# SAMA7G54D4GN8 register map
Vendor: Microchip Technology; Series: SAMA7G5; File version: 0
Registers are 32-bit, read-write, reset 0x0 unless marked. A register's access mark holds for its fields unless they carry their own. Offsets are from the block's base; [hi:lo] are bit positions; {n}, {i} and the like mark numbered series; 'fields as' and 'values as' point back to an identical list.

## EIC — External Interrupt Controller
Base 0xE1628000
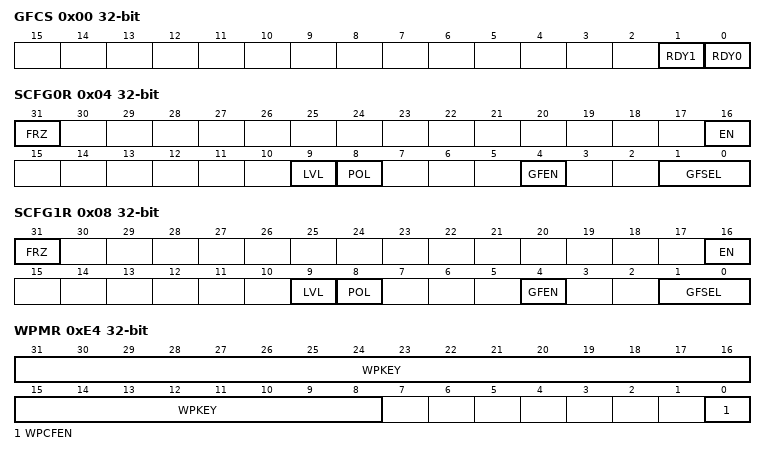
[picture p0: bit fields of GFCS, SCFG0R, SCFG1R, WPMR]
0x00 GFCS ro — Glitch Filter Configuration Status Register
  [1] RDY1 — Filter 1 Configuration Ready
    0=The interrupt line x glitch filter is not yet ready for use due to a previous write to IP_Acronym_SCFGxR, or the glitch filter is not implemented for this interrupt line. The glitch filter must not be reprogrammed in EIC_SCFGxR.; 1=The interrupt line x glitch filter configuration is done and the glitch filter is active. The glitch filter can be programmed in EIC_SCFGxR.
  [0] RDY0 — Filter 0 Configuration Ready
    values as RDY1
0x04 SCFG0R — Source Configuration Register 0
  [31] FRZ — Interrupt Line Freeze
    0=No effect; 1=EIC_SCFGxR is frozen until hardware reset
  [16] EN — Source Enable
    0=The EIC source x is disabled. Any source edge or level detection is discarded.; 1=The EIC source x is enabled
  [9] LVL — Level Detection
    0=The EIC source x interrupt status is set on a valid source edge; 1=The EIC source x interrupt status is set on a valid source level
  [8] POL — Polarity
    0=The EIC source x is active low if LVL is set, or active on falling edge if LVL is cleared; 1=The EIC source x is active high if LVL is set, or active on rising edge if LVL is cleared
  [4] GFEN — Glitch Filter Enable
    0=The glitch filter is disabled or not implemented for EIC source x. Any source x change is forwarded as is to the source detection logic.; 1=The glitch filter is enabled for EIC source x. The EIC source x glitches are filtered according to Section 7.1 'Interrupt Line Characteristics'.
  [1:0] GFSEL — Glitch Filter Selector
0x08 SCFG1R — Source Configuration Register 1
  fields as SCFG0R
0xE4 WPMR — Write Protection Mode Register
  [31:8] WPKEY — Write Protection Key
    0x454943=PASSWD (Writing any other value in this field aborts the write operation of the WPCFEN and WPITEN bit. Always reads as 0.)
  [0] WPCFEN — Write Protection Configuration Enable
    0=Disables the write protection of the configuration registers if WPKEY corresponds to 0x454943 ('EIC' in ASCII); 1=Enables the write protection of the configuration registers if WPKEY corresponds to 0x454943 ('EIC' in ASCII)
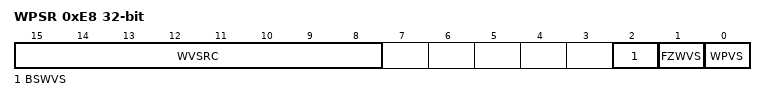
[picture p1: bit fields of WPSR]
0xE8 WPSR ro — Write Protection Status Register
  [15:8] WVSRC — Write Violation Source
  [2] BSWVS — Busy Register Write Violation Status
    0=No write access violation of a busy register has occurred since the last read of EIC_WPSR; 1=A write access violation of a busy register has occurred since the last read of EIC_WPSR. The associated violation is reported into WVSRC.
  [1] FZWVS — Frozen Register Write Violation Status
    0=No write access violation of a frozen register has occurred since the last read of EIC_WPSR; 1=A write access violation of a frozen register has occurred since the last read of EIC_WPSR. The associated violation is reported into WVSRC.
  [0] WPVS — Write Protection Register Violation Status
    0=No write protection violation has occurred since the last read of EIC_WPSR; 1=A write protection violation has occurred since the last read of EIC_WPSR. The associated violation is reported into WVSRC.

## GPBR — General Purpose Backup Registers
Base 0xE001D060
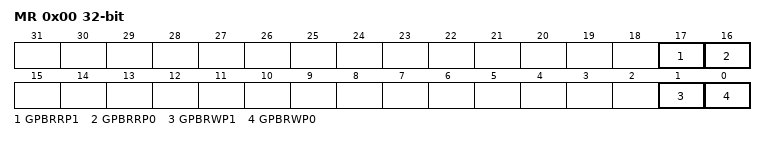
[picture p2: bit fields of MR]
0x00 MR — GPBR Mode Register
  [17] GPBRRP1 — GPBRx Read Protection
    0=The content of the corresponding GPBR register (32-bit part-select) can be read; 1=The corresponding GPBR register (32-bit part-select) always returns zero when read
  [16] GPBRRP0 — GPBRx Read Protection
    values as GPBRRP1
  [1] GPBRWP1 — GPBRx Write Protection
    0=The corresponding GPBR register (32-bit part-select) can be written; 1=The corresponding GPBR register (32-bit part-select) is write-protected
  [0] GPBRWP0 — GPBRx Write Protection
    values as GPBRWP1
0x04 FCLR — GPBR Full Clear Register
  [0] FCLR — Full Clear Enable
    0=SYS_GPBR0 is immediately cleared in case of fast wake-up pin tamper event; 1=SYS_GPBR0 and SYS_GPBR1 are immediately cleared in case of fast wake-up pin tamper event
{0x8+4i} SYS_GPBR[{i}] (i=0..1) — General Purpose Backup Register x
  [31:0] GPBR_VALUE — Value of SYS_GPBRx

## Notices in the file
Copyright (c) 2026 Microchip Technology Inc.
SPDX-License-Identifier: Apache-2.0
Licensed under the Apache License, Version 2.0 (the "License");
you may not use this file except in compliance with the License.
You may obtain a copy of the License at
http://www.apache.org/licenses/LICENSE-2.0
Unless required by applicable law or agreed to in writing, software
distributed under the License is distributed on an "AS IS" BASIS,
WITHOUT WARRANTIES OR CONDITIONS OF ANY KIND, either express or implied.
See the License for the specific language governing permissions and
limitations under the License.
